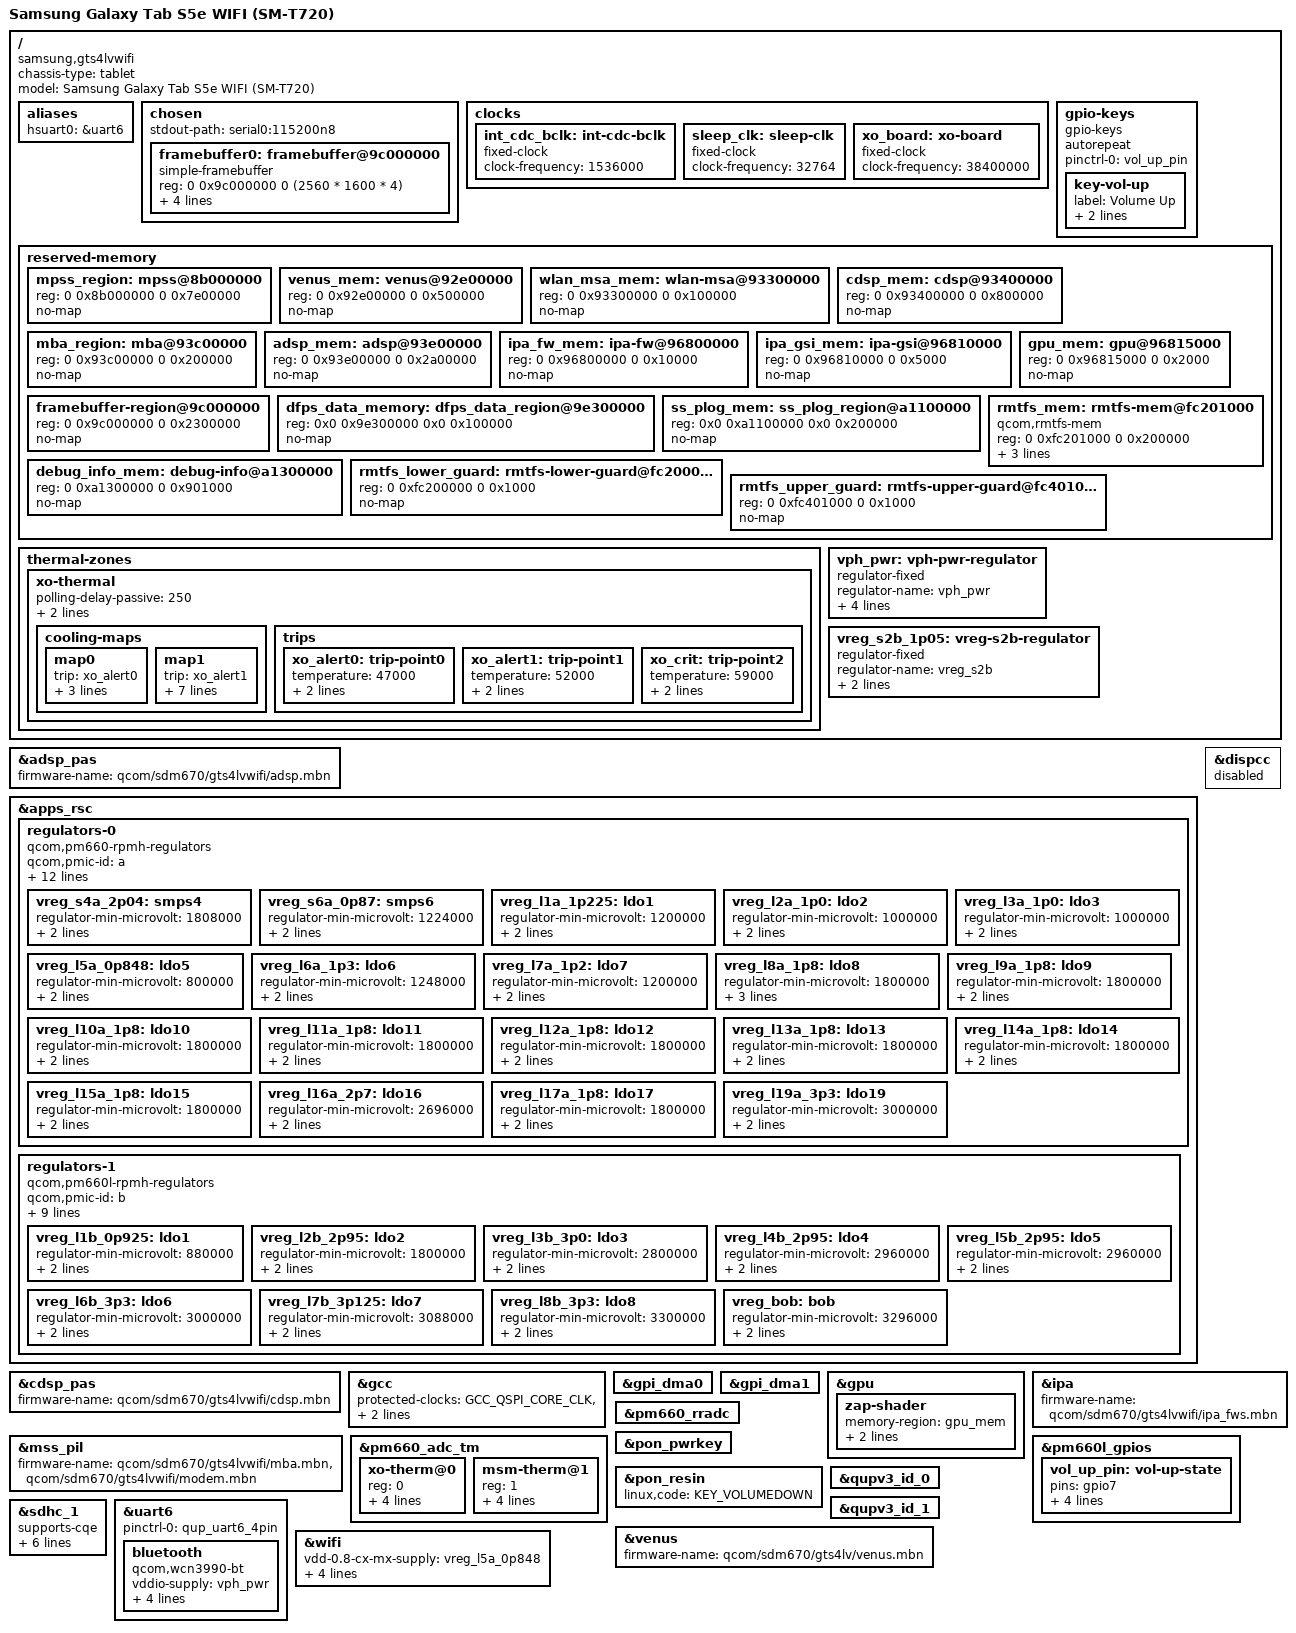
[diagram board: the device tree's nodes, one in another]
// SPDX-License-Identifier: GPL-2.0
/*
 * Device tree for Samsung Galaxy Tab S5e WIFI (SM-T720), derived from sdm670-google-common device tree.
 *
 * Copyright (c) 2025, The Linux Foundation. All rights reserved.
 */

/dts-v1/;

#include <dt-bindings/firmware/qcom,scm.h>
#include <dt-bindings/gpio/gpio.h>
#include <dt-bindings/input/input.h>
#include <dt-bindings/pinctrl/qcom,pmic-gpio.h>
#include <dt-bindings/power/qcom-rpmpd.h>
#include "sdm670.dtsi"
#include "pm660.dtsi"
#include "pm660l.dtsi"

/delete-node/ &ipa_fw_mem;
/delete-node/ &ipa_gsi_mem;
/delete-node/ &gpu_mem;
/delete-node/ &rmtfs_mem;


/ {
	chassis-type = "tablet";

	model = "Samsung Galaxy Tab S5e WIFI (SM-T720)";
	compatible = "samsung,gts4lvwifi", "qcom,sdm670";

	aliases {
		hsuart0 = &uart6;
	};


	chosen {
		stdout-path = "serial0:115200n8";

		#address-cells = <2>;
		#size-cells = <2>;
		ranges;

		framebuffer0: framebuffer@9c000000 {
			compatible = "simple-framebuffer";
			reg = <0 0x9c000000 0 (2560 * 1600 * 4)>;
			width = <2560>;
			height = <1600>;
			stride = <(2560 * 4)>;
			format = "a8r8g8b8";
			status = "okay";
		};
	};

	clocks {
		int_cdc_bclk: int-cdc-bclk {
			compatible = "fixed-clock";
			#clock-cells = <0>;
			clock-frequency = <1536000>;
		};

		sleep_clk: sleep-clk {
			compatible = "fixed-clock";
			#clock-cells = <0>;
			clock-frequency = <32764>;
		};

		xo_board: xo-board {
			compatible = "fixed-clock";
			#clock-cells = <0>;
			clock-frequency = <38400000>;
		};
	};

	gpio-keys {
		compatible = "gpio-keys";
		autorepeat;

		pinctrl-names = "default";
		pinctrl-0 = <&vol_up_pin>;

		key-vol-up {
			label = "Volume Up";
			linux,code = <KEY_VOLUMEUP>;
			gpios = <&pm660l_gpios 7 GPIO_ACTIVE_LOW>;
		};
	};

	reserved-memory {
		#address-cells = <2>;
		#size-cells = <2>;

		mpss_region: mpss@8b000000 {
			reg = <0 0x8b000000 0 0x7e00000>;
			no-map;
		};

		venus_mem: venus@92e00000 {
			reg = <0 0x92e00000 0 0x500000>;
			no-map;
		};

                wlan_msa_mem: wlan-msa@93300000 {
			reg = <0 0x93300000 0 0x100000>;
			no-map;
		};

		cdsp_mem: cdsp@93400000 {
			reg = <0 0x93400000 0 0x800000>;
			no-map;
		};

		mba_region: mba@93c00000 {
			reg = <0 0x93c00000 0 0x200000>;
			no-map;
		};

		adsp_mem: adsp@93e00000 {
			reg = <0 0x93e00000 0 0x2a00000>;
			no-map;
		};

		ipa_fw_mem: ipa-fw@96800000 {
			reg = <0 0x96800000 0 0x10000>;
			no-map;
		};

		ipa_gsi_mem: ipa-gsi@96810000 {
			reg = <0 0x96810000 0 0x5000>;
			no-map;
		};

		gpu_mem: gpu@96815000 {
			reg = <0 0x96815000 0 0x2000>;
			no-map;
		};

		framebuffer-region@9c000000 {
			reg = <0 0x9c000000 0 0x2300000>;
			no-map;
		};

		dfps_data_memory: dfps_data_region@9e300000 {
			reg = <0x0 0x9e300000 0x0 0x100000>;
			no-map;
		};

		ss_plog_mem: ss_plog_region@a1100000 {
			reg = <0x0 0xa1100000 0x0 0x200000>;
			no-map;
		};

		/* Also includes ramoops regions */
		debug_info_mem: debug-info@a1300000 {
			reg = <0 0xa1300000 0 0x901000>;
			no-map;
		};

		/*
		 * The rmtfs_mem needs to be guarded due to "XPU limitations"
		 * it is otherwise possible for an allocation adjacent to the
		 * rmtfs_mem region to trigger an XPU violation, causing a
		 * crash.
		 */
		rmtfs_lower_guard: rmtfs-lower-guard@fc200000 {
			reg = <0 0xfc200000 0 0x1000>;
			no-map;
		};

		/*
		 * The rmtfs memory region in downstream is 'dynamically
		 * allocated' but given the same address every time. Hard code
		 * it as this address is where the modem firmware expects it to
		 * be.
		 */
		rmtfs_mem: rmtfs-mem@fc201000 {
			compatible = "qcom,rmtfs-mem";
			reg = <0 0xfc201000 0 0x200000>;
			no-map;

			qcom,client-id = <1>;
			qcom,vmid = <QCOM_SCM_VMID_MSS_MSA>;
		};

		rmtfs_upper_guard: rmtfs-upper-guard@fc401000 {
			reg = <0 0xfc401000 0 0x1000>;
			no-map;
		};
	};

	thermal-zones {
		xo-thermal {
			polling-delay-passive = <250>;
			polling-delay = <1000>;

			thermal-sensors = <&pm660_adc_tm 0>;

			cooling-maps {
				map0 {
					trip = <&xo_alert0>;
					cooling-device = <&cpu6 THERMAL_NO_LIMIT THERMAL_NO_LIMIT>,
							 <&cpu7 THERMAL_NO_LIMIT THERMAL_NO_LIMIT>;

				};

				map1 {
					trip = <&xo_alert1>;
					cooling-device = <&cpu0 THERMAL_NO_LIMIT THERMAL_NO_LIMIT>,
							 <&cpu1 THERMAL_NO_LIMIT THERMAL_NO_LIMIT>,
							 <&cpu2 THERMAL_NO_LIMIT THERMAL_NO_LIMIT>,
							 <&cpu3 THERMAL_NO_LIMIT THERMAL_NO_LIMIT>,
							 <&cpu4 THERMAL_NO_LIMIT THERMAL_NO_LIMIT>,
							 <&cpu5 THERMAL_NO_LIMIT THERMAL_NO_LIMIT>;

				};
			};

			trips {
				xo_alert0: trip-point0 {
					temperature = <47000>;
					hysteresis = <1000>;
					type = "passive";
				};

				xo_alert1: trip-point1 {
					temperature = <52000>;
					hysteresis = <1000>;
					type = "passive";
				};

				xo_crit: trip-point2 {
					temperature = <59000>;
					hysteresis = <1000>;
					type = "critical";
				};
			};
		};
	};

	vph_pwr: vph-pwr-regulator {
		compatible = "regulator-fixed";
		regulator-name = "vph_pwr";
		regulator-min-microvolt = <3312000>;
		regulator-max-microvolt = <3312000>;

		regulator-always-on;
		regulator-boot-on;
	};

	/*
	 * Supply map from xiaomi-lavender specifies this as the supply for
	 * ldob1, ldob9, ldob10, ldoa2, and ldoa3, while downstream specifies
	 * this as a power domain. Set this as a fixed regulator with the same
	 * voltage as lavender until display is needed to avoid unneccessarily
	 * using a deprecated binding (regulator-fixed-domain).
	 */
	vreg_s2b_1p05: vreg-s2b-regulator {
		compatible = "regulator-fixed";
		regulator-name = "vreg_s2b";
		regulator-min-microvolt = <1050000>;
		regulator-max-microvolt = <1050000>;
	};
};

&adsp_pas {
	status = "okay";
	firmware-name = "qcom/sdm670/gts4lvwifi/adsp.mbn";
};

&apps_rsc {
	regulators-0 {
		compatible = "qcom,pm660-rpmh-regulators";
		qcom,pmic-id = "a";

		vdd-s1-supply = <&vph_pwr>;
		vdd-s2-supply = <&vph_pwr>;
		vdd-s3-supply = <&vph_pwr>;
		vdd-s4-supply = <&vph_pwr>;
		vdd-s5-supply = <&vph_pwr>;
		vdd-s6-supply = <&vph_pwr>;

		vdd-l1-l6-l7-supply = <&vreg_s6a_0p87>;
		vdd-l2-l3-supply = <&vreg_s2b_1p05>;
		vdd-l5-supply = <&vreg_s2b_1p05>;
		vdd-l8-l9-l10-l11-l12-l13-l14-supply = <&vreg_s4a_2p04>;
		vdd-l15-l16-l17-l18-l19-supply = <&vreg_bob>;

		/*
		 * S1A (FTAPC0), S2A (FTAPC1), S3A (HFAPC1) are managed
		 * by the Core Power Reduction hardened (CPRh) and the
		 * Operating State Manager (OSM) HW automatically.
		 */

		vreg_s4a_2p04: smps4 {
			regulator-min-microvolt = <1808000>;
			regulator-max-microvolt = <2040000>;
			regulator-enable-ramp-delay = <200>;
		};

		vreg_s6a_0p87: smps6 {
			regulator-min-microvolt = <1224000>;
			regulator-max-microvolt = <1352000>;
			regulator-enable-ramp-delay = <150>;
		};

		/* LDOs */
		vreg_l1a_1p225: ldo1 {
			regulator-min-microvolt = <1200000>;
			regulator-max-microvolt = <1250000>;
			regulator-enable-ramp-delay = <250>;
		};

		vreg_l2a_1p0: ldo2 {
			regulator-min-microvolt = <1000000>;
			regulator-max-microvolt = <1000000>;
			regulator-enable-ramp-delay = <250>;
		};

		vreg_l3a_1p0: ldo3 {
			regulator-min-microvolt = <1000000>;
			regulator-max-microvolt = <1000000>;
			regulator-enable-ramp-delay = <250>;
		};

		vreg_l5a_0p848: ldo5 {
			regulator-min-microvolt = <800000>;
			regulator-max-microvolt = <800000>;
			regulator-enable-ramp-delay = <250>;
		};

		vreg_l6a_1p3: ldo6 {
			regulator-min-microvolt = <1248000>;
			regulator-max-microvolt = <1304000>;
			regulator-enable-ramp-delay = <250>;
		};

		vreg_l7a_1p2: ldo7 {
			regulator-min-microvolt = <1200000>;
			regulator-max-microvolt = <1200000>;
			regulator-enable-ramp-delay = <250>;
		};

		vreg_l8a_1p8: ldo8 {
			regulator-min-microvolt = <1800000>;
			regulator-max-microvolt = <1800000>;
			regulator-enable-ramp-delay = <250>;
			regulator-always-on;
		};

		vreg_l9a_1p8: ldo9 {
			regulator-min-microvolt = <1800000>;
			regulator-max-microvolt = <1800000>;
			regulator-enable-ramp-delay = <250>;
		};

		vreg_l10a_1p8: ldo10 {
			regulator-min-microvolt = <1800000>;
			regulator-max-microvolt = <1800000>;
			regulator-enable-ramp-delay = <250>;
		};

		vreg_l11a_1p8: ldo11 {
			regulator-min-microvolt = <1800000>;
			regulator-max-microvolt = <1800000>;
			regulator-enable-ramp-delay = <250>;
		};

		vreg_l12a_1p8: ldo12 {
			regulator-min-microvolt = <1800000>;
			regulator-max-microvolt = <1800000>;
			regulator-enable-ramp-delay = <250>;
		};

		vreg_l13a_1p8: ldo13 {
			regulator-min-microvolt = <1800000>;
			regulator-max-microvolt = <1800000>;
			regulator-enable-ramp-delay = <250>;
		};

		vreg_l14a_1p8: ldo14 {
			regulator-min-microvolt = <1800000>;
			regulator-max-microvolt = <1800000>;
			regulator-enable-ramp-delay = <250>;
		};

		vreg_l15a_1p8: ldo15 {
			regulator-min-microvolt = <1800000>;
			regulator-max-microvolt = <2950000>;
			regulator-enable-ramp-delay = <250>;
		};

		vreg_l16a_2p7: ldo16 {
			regulator-min-microvolt = <2696000>;
			regulator-max-microvolt = <2696000>;
			regulator-enable-ramp-delay = <250>;
		};

		vreg_l17a_1p8: ldo17 {
			regulator-min-microvolt = <1800000>;
			regulator-max-microvolt = <2950000>;
			regulator-enable-ramp-delay = <250>;
		};

		vreg_l19a_3p3: ldo19 {
			regulator-min-microvolt = <3000000>;
			regulator-max-microvolt = <3312000>;
			regulator-enable-ramp-delay = <250>;
		};
	};

	regulators-1 {
		compatible = "qcom,pm660l-rpmh-regulators";
		qcom,pmic-id = "b";

		vdd-s1-supply = <&vph_pwr>;
		vdd-s2-supply = <&vph_pwr>;
		vdd-s3-s4-supply = <&vph_pwr>;
		vdd-s5-supply = <&vph_pwr>;

		vdd-l1-l9-l10-supply = <&vreg_s2b_1p05>;
		vdd-l2-supply = <&vreg_bob>;
		vdd-l3-l5-l7-l8-supply = <&vreg_bob>;
		vdd-l4-l6-supply = <&vreg_bob>;
		vdd-bob-supply = <&vph_pwr>;

		/* LDOs */
		vreg_l1b_0p925: ldo1 {
			regulator-min-microvolt = <880000>;
			regulator-max-microvolt = <900000>;
			regulator-enable-ramp-delay = <250>;
		};

		vreg_l2b_2p95: ldo2 {
			regulator-min-microvolt = <1800000>;
			regulator-max-microvolt = <2960000>;
			regulator-enable-ramp-delay = <250>;
		};

		vreg_l3b_3p0: ldo3 {
			regulator-min-microvolt = <2800000>;
			regulator-max-microvolt = <3008000>;
			regulator-enable-ramp-delay = <250>;
		};

		vreg_l4b_2p95: ldo4 {
			regulator-min-microvolt = <2960000>;
			regulator-max-microvolt = <2960000>;
			regulator-enable-ramp-delay = <250>;
		};

		vreg_l5b_2p95: ldo5 {
			regulator-min-microvolt = <2960000>;
			regulator-max-microvolt = <2960000>;
			regulator-enable-ramp-delay = <250>;
		};

		vreg_l6b_3p3: ldo6 {
			regulator-min-microvolt = <3000000>;
			regulator-max-microvolt = <3300000>;
			regulator-enable-ramp-delay = <250>;
		};

		vreg_l7b_3p125: ldo7 {
			regulator-min-microvolt = <3088000>;
			regulator-max-microvolt = <3100000>;
			regulator-enable-ramp-delay = <250>;
		};

		vreg_l8b_3p3: ldo8 {
			regulator-min-microvolt = <3300000>;
			regulator-max-microvolt = <3312000>;
			regulator-enable-ramp-delay = <250>;
		};

		/*
		 * Downstream specifies a fixed voltage of 3.312 V, but the
		 * PMIC4 BOB ranges don't support that. Widen the range a
		 * little to avoid adding a new BOB regulator type.
		 */
		vreg_bob: bob {
			regulator-min-microvolt = <3296000>;
			regulator-max-microvolt = <3328000>;
			regulator-enable-ramp-delay = <500>;
		};
	};
};

&dispcc {
	status = "disabled";
};

&cdsp_pas {
	status = "okay";
	firmware-name = "qcom/sdm670/gts4lvwifi/cdsp.mbn";
};

&gcc {
	protected-clocks = <GCC_QSPI_CORE_CLK>,
			   <GCC_QSPI_CORE_CLK_SRC>,
			   <GCC_QSPI_CNOC_PERIPH_AHB_CLK>;
};

&gpi_dma0 {
	status = "okay";
};

&gpi_dma1 {
	status = "okay";
};

&gpu {
    	status = "okay";

    	zap-shader {
        	memory-region = <&gpu_mem>;
        	firmware-name = "qcom/sdm670/gts4lvwifi/a615_zap.mbn";
    	};
};

&ipa {
    	firmware-name = "qcom/sdm670/gts4lvwifi/ipa_fws.mbn";
    	status = "okay";
};

// Missing panel (AMSA05RB01) drivers

&mss_pil {
    	firmware-name = "qcom/sdm670/gts4lvwifi/mba.mbn", "qcom/sdm670/gts4lvwifi/modem.mbn";
    	status = "okay";
};

&pm660_adc_tm {
	status = "okay";

	xo-therm@0 {
		reg = <0>;
		io-channels = <&pm660_adc ADC5_XO_THERM_100K_PU>;
		qcom,hw-settle-time-us = <200>;
		qcom,pre-scaling = <1 1>;
		qcom,ratiometric;
	};

	msm-therm@1 {
		reg = <1>;
		io-channels = <&pm660_adc ADC5_AMUX_THM1_100K_PU>;
		qcom,hw-settle-time-us = <200>;
		qcom,pre-scaling = <1 1>;
		qcom,ratiometric;
	};
};

// Missing Charger/Fuelgauge (SM5705) drivers

&pm660_rradc {
	status = "okay";
};

&pm660l_gpios {
	vol_up_pin: vol-up-state {
		pins = "gpio7";
		function = "normal";
		qcom,drive-strength = <PMIC_GPIO_STRENGTH_NO>;
		input-enable;
		bias-pull-up;
	};
};

&pon_pwrkey {
	status = "okay";
};

&pon_resin {
	linux,code = <KEY_VOLUMEDOWN>;
	status = "okay";
};

&qupv3_id_0 {
	status = "okay";
};

&qupv3_id_1 {
	status = "okay";
};

&sdhc_1 {
	supports-cqe;
	mmc-hs200-1_8v;
	mmc-hs400-1_8v;
	mmc-ddr-1_8v;

	qcom,ddr-config = <0xc3040873>;

	vmmc-supply = <&vreg_l4b_2p95>;
	vqmmc-supply = <&vreg_l8a_1p8>;

	status = "okay";
};

&uart6 {
	pinctrl-0 = <&qup_uart6_4pin>;
	status = "okay";

	bluetooth {
		compatible = "qcom,wcn3990-bt";
		vddio-supply = <&vph_pwr>;
		vddxo-supply = <&vreg_l9a_1p8>;
		vddrf-supply = <&vreg_l6a_1p3>;
		vddch0-supply = <&vreg_l19a_3p3>;
		max-speed = <3200000>;
	};
};

// USB2 is routed through PMIC (SM5705 / S2MM005)
// USB3 is still missing for sdm670

&venus {
	firmware-name = "qcom/sdm670/gts4lv/venus.mbn";
	status = "okay";
};

&wifi {
	vdd-0.8-cx-mx-supply = <&vreg_l5a_0p848>;
	vdd-1.8-xo-supply = <&vreg_l9a_1p8>;
	vdd-1.3-rfa-supply = <&vreg_l6a_1p3>;
	vdd-3.3-ch0-supply = <&vreg_l19a_3p3>;

	qcom,snoc-host-cap-8bit-quirk;

	status = "okay";
};
